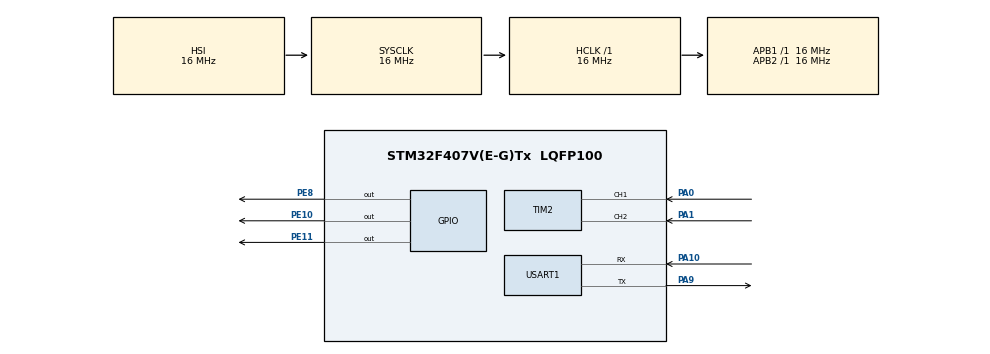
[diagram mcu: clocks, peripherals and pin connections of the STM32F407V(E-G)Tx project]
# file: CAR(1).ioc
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Mcu.Family=STM32F4
Mcu.Name=STM32F407V(E-G)Tx
Mcu.Package=LQFP100
NVIC.PriorityGroup=NVIC_PRIORITYGROUP_4
NVIC.TIM1_UP_TIM10_IRQn=true\:0\:0\:false\:false\:true\:true\:true\:true
NVIC.TIM3_IRQn=true\:0\:0\:false\:false\:true\:true\:true\:true
PA0-WKUP.Signal=S_TIM2_CH1_ETR
PA1.Signal=S_TIM2_CH2
PA10.Mode=Asynchronous
PA10.Signal=USART1_RX
PA13.Mode=Serial_Wire
PA13.Signal=SYS_JTMS-SWDIO
PA14.Mode=Serial_Wire
PA14.Signal=SYS_JTCK-SWCLK
PA9.Mode=Asynchronous
PA9.Signal=USART1_TX
PE10.GPIO_ModeDefaultOutputPP=GPIO_MODE_OUTPUT_OD
PE10.GPIO_PuPd=GPIO_NOPULL
PE10.Signal=GPIO_Output
PE11.GPIO_ModeDefaultOutputPP=GPIO_MODE_OUTPUT_OD
PE11.GPIO_PuPd=GPIO_NOPULL
PE11.Signal=GPIO_Output
PE8.GPIO_ModeDefaultOutputPP=GPIO_MODE_OUTPUT_OD
PE8.GPIO_PuPd=GPIO_NOPULL
PE8.Signal=GPIO_Output
PH0-OSC_IN.Mode=HSE-External-Oscillator
PH0-OSC_IN.Signal=RCC_OSC_IN
PH1-OSC_OUT.Mode=HSE-External-Oscillator
PH1-OSC_OUT.Signal=RCC_OSC_OUT
ProjectManager.HeapSize=0x200
ProjectManager.StackSize=0x400
ProjectManager.TargetToolchain=MDK-ARM V5.32
RCC.AHBFreq_Value=16000000
RCC.APB1Freq_Value=16000000
RCC.APB2Freq_Value=16000000
RCC.CortexFreq_Value=16000000
RCC.HSE_VALUE=25000000
RCC.HSI_VALUE=16000000
RCC.LSE_VALUE=32768
RCC.SYSCLKFreq_VALUE=16000000
RCC.VCOOutputFreq_Value=192000000
SH.S_TIM2_CH1_ETR.0=TIM2_CH1,Encoder_Interface
SH.S_TIM2_CH2.0=TIM2_CH2,Encoder_Interface
TIM1.AutoReloadPreload=TIM_AUTORELOAD_PRELOAD_ENABLE
TIM1.Period=10000
TIM1.Prescaler=167
TIM2.IC2Polarity=TIM_ICPOLARITY_FALLING
TIM3.AutoReloadPreload=TIM_AUTORELOAD_PRELOAD_ENABLE
TIM3.Period=10000
TIM3.Prescaler=167
USART1.VirtualMode=VM_ASYNC
VP_TIM1_VS_ClockSourceINT.Mode=Internal
VP_TIM3_VS_ClockSourceINT.Mode=Internal
board=custom

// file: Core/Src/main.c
/* USER CODE BEGIN Header */
/**
  ******************************************************************************
  * @file           : main.c
  * @brief          : Main program body
  ******************************************************************************
  * @attention
  *
  * Copyright (c) 2026 STMicroelectronics.
  * All rights reserved.
  *
  * This software is licensed under terms that can be found in the LICENSE file
  * in the root directory of this software component.
  * If no LICENSE file comes with this software, it is provided AS-IS.
  *
  ******************************************************************************
  */
/* USER CODE END Header */
#include "main.h"
#include "tim.h"
#include "usart.h"
#include "gpio.h"

/* USER CODE BEGIN PTD */
uint8_t a[1] = {1};
/* USER CODE END PTD */

void SystemClock_Config(void);

int main(void)
{

  /* MCU Configuration--------------------------------------------------------*/

  /* Reset of all peripherals, Initializes the Flash interface and the Systick. */
  HAL_Init();

  /* Configure the system clock */
  SystemClock_Config();

  /* Initialize all configured peripherals */
  MX_GPIO_Init();
  MX_TIM1_Init();
  MX_TIM2_Init();
  MX_TIM3_Init();
  MX_USART1_UART_Init();
  /* USER CODE BEGIN 2 */
  HAL_TIM_Encoder_Start(&htim2, TIM_CHANNEL_1);

//  HAL_TIM_Base_Start(&htim3);

  HAL_TIM_Base_Start(&htim1);
	HAL_TIM_Base_Start_IT(&htim3);

  HAL_TIM_PWM_Start(&htim1, TIM_CHANNEL_1);
  HAL_TIM_PWM_Start(&htim1, TIM_CHANNEL_2);

  HAL_GPIO_WritePin(GPIOE, GPIO_PIN_8, GPIO_PIN_SET);
  HAL_GPIO_WritePin(GPIOE, GPIO_PIN_10, GPIO_PIN_SET);
  HAL_GPIO_WritePin(GPIOE, GPIO_PIN_11, GPIO_PIN_RESET);

  __HAL_TIM_SET_COMPARE(&htim1, TIM_CHANNEL_1, 600);
  /* USER CODE END 2 */

  /* Infinite loop */
  /* USER CODE BEGIN WHILE */
  while (1)
  {
//		HAL_UART_Transmit(&huart1,a,1,HAL_MAX_DELAY);
    /* USER CODE END WHILE */

  }
}

void SystemClock_Config(void)
{
  RCC_OscInitTypeDef RCC_OscInitStruct = {0};
  RCC_ClkInitTypeDef RCC_ClkInitStruct = {0};

  /** Configure the main internal regulator output voltage
  */
  __HAL_RCC_PWR_CLK_ENABLE();
  __HAL_PWR_VOLTAGESCALING_CONFIG(PWR_REGULATOR_VOLTAGE_SCALE1);

  /** Initializes the RCC Oscillators according to the specified parameters
  * in the RCC_OscInitTypeDef structure.
  */
  RCC_OscInitStruct.OscillatorType = RCC_OSCILLATORTYPE_HSI;
  RCC_OscInitStruct.HSIState = RCC_HSI_ON;
  RCC_OscInitStruct.HSICalibrationValue = RCC_HSICALIBRATION_DEFAULT;
  RCC_OscInitStruct.PLL.PLLState = RCC_PLL_NONE;
  if (HAL_RCC_OscConfig(&RCC_OscInitStruct) != HAL_OK)
  {
    Error_Handler();
  }

  /** Initializes the CPU, AHB and APB buses clocks
  */
  RCC_ClkInitStruct.ClockType = RCC_CLOCKTYPE_HCLK|RCC_CLOCKTYPE_SYSCLK
                              |RCC_CLOCKTYPE_PCLK1|RCC_CLOCKTYPE_PCLK2;
  RCC_ClkInitStruct.SYSCLKSource = RCC_SYSCLKSOURCE_HSI;
  RCC_ClkInitStruct.AHBCLKDivider = RCC_SYSCLK_DIV1;
  RCC_ClkInitStruct.APB1CLKDivider = RCC_HCLK_DIV1;
  RCC_ClkInitStruct.APB2CLKDivider = RCC_HCLK_DIV1;

  if (HAL_RCC_ClockConfig(&RCC_ClkInitStruct, FLASH_LATENCY_0) != HAL_OK)
  {
    Error_Handler();
  }
}

/* USER CODE BEGIN 4 */
void HAL_TIM_PeriodElapsedCallback(TIM_HandleTypeDef *htim)
{
    if (htim == &htim3)  // TIM3定时中断
    {
			HAL_UART_Transmit(&huart1,a,1,HAL_MAX_DELAY);
		}
}
/* USER CODE END 4 */

void Error_Handler(void)
{
  __disable_irq();
  while (1)
  {
  }
}
